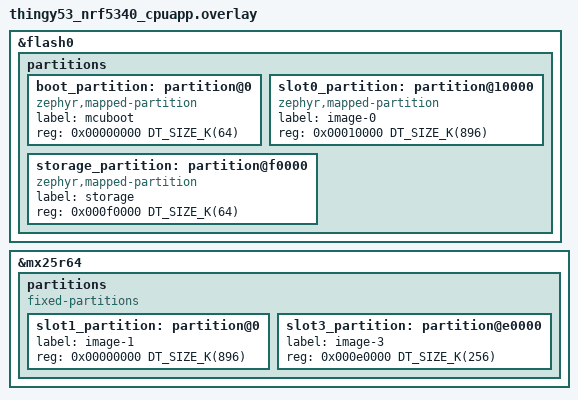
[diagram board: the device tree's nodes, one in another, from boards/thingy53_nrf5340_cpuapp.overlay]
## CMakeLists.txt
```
#
# Copyright (c) 2022 Nordic Semiconductor ASA
#
# SPDX-License-Identifier: LicenseRef-Nordic-5-Clause
#

cmake_minimum_required(VERSION 3.20.0)

find_package(Zephyr REQUIRED HINTS $ENV{ZEPHYR_BASE})
project(wifi_ble_provisioning)

target_sources(app PRIVATE src/main.c)

zephyr_library_include_directories($<TARGET_PROPERTY:wifi_prov_core,BINARY_DIR>)

target_link_libraries(app PRIVATE wifi_prov_ble)
```

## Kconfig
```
#
# Copyright (c) 2022 Nordic Semiconductor ASA
#
# SPDX-License-Identifier: LicenseRef-Nordic-5-Clause
#
menu "Wi-Fi Provisioning Sample"

config WIFI_PROV_ADV_DATA_UPDATE
	bool "Enable periodic update of advertisement data"
	default y

if WIFI_PROV_ADV_DATA_UPDATE

	config WIFI_PROV_ADV_DATA_UPDATE_INTERVAL
		int "Periodic update interval in second"
		default 5

endif # WIFI_PROV_ADV_DATA_UPDATE

endmenu

source "Kconfig.zephyr"
```

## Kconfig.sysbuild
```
#
# Copyright (c) 2023 Nordic Semiconductor
#
# SPDX-License-Identifier: LicenseRef-Nordic-5-Clause
#

source "${ZEPHYR_NRF_MODULE_DIR}/samples/wifi/Kconfig.sysbuild.nrf70"
source "share/sysbuild/Kconfig"

config NRF_DEFAULT_IPC_RADIO
	default y
```

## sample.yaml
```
sample:
  description: Bluetooth Low Energy Wi-Fi provision sample
  name: Bluetooth LE Wi-Fi provision
tests:
  sample.nrf7002.ble-wifi-provision:
    sysbuild: true
    build_only: true
    integration_platforms:
      - nrf7002dk/nrf5340/cpuapp
    platform_allow: nrf7002dk/nrf5340/cpuapp
    tags:
      - ci_build
      - sysbuild
      - ci_samples_wifi
  sample.nrf7001.ble-wifi-provision:
    sysbuild: true
    build_only: true
    integration_platforms:
      - nrf7002dk/nrf5340/cpuapp/nrf7001
    platform_allow: nrf7002dk/nrf5340/cpuapp/nrf7001
    tags:
      - ci_build
      - sysbuild
      - ci_samples_wifi
    skip: true
  sample.nrf7002_eks.ble-wifi-provision:
    sysbuild: true
    build_only: true
    extra_args: SHIELD=nrf7002ek
    integration_platforms:
      - nrf5340dk/nrf5340/cpuapp
    platform_allow: nrf5340dk/nrf5340/cpuapp
    tags:
      - ci_build
      - sysbuild
      - ci_samples_wifi
  sample.nrf7001_eks.ble-wifi-provision:
    sysbuild: true
    build_only: true
    extra_args: SHIELD=nrf7002ek_nrf7001
    integration_platforms:
      - nrf5340dk/nrf5340/cpuapp
    platform_allow: nrf5340dk/nrf5340/cpuapp
    tags:
      - ci_build
      - sysbuild
      - ci_samples_wifi
  sample.nrf7002_eb.thingy53.ble-wifi-provision:
    sysbuild: true
    build_only: true
    extra_args: ble_SHIELD=nrf7002eb
    integration_platforms:
      - thingy53/nrf5340/cpuapp
    platform_allow: thingy53/nrf5340/cpuapp
    tags:
      - ci_build
      - sysbuild
      - ci_samples_wifi
  sample.nrf7002eb2.nrf54l15.ble-wifi-provision:
    sysbuild: true
    build_only: true
    extra_args:
      - ble_SHIELD="nrf7002eb2"
      - ble_SNIPPET=nrf70-wifi
      - CONFIG_NRF_WIFI_CTRL_HEAP_SIZE=25000
    integration_platforms:
      - nrf54l15dk/nrf54l15/cpuapp
    platform_allow:
      - nrf54l15dk/nrf54l15/cpuapp
    tags:
      - ci_build
      - sysbuild
      - ci_samples_wifi
  sample.nrf7002eb_interposer_p1.nrf54h20.ble-wifi-provision:
    sysbuild: true
    build_only: true
    extra_args:
      - ble_SHIELD="nrf7002eb_interposer_p1;nrf7002eb"
      - ble_SNIPPET=nrf70-wifi
    integration_platforms:
      - nrf54h20dk/nrf54h20/cpuapp
    platform_allow:
      - nrf54h20dk/nrf54h20/cpuapp
    tags:
      - ci_build
      - sysbuild
      - ci_samples_wifi
  sample.54lm20dk.nrf7002eb2.ble-wifi-provision:
    sysbuild: true
    build_only: true
    extra_args:
      - ble_SHIELD="nrf7002eb2"
    integration_platforms:
      - nrf54lm20dk/nrf54lm20a/cpuapp
      - nrf54lm20dk/nrf54lm20b/cpuapp
    platform_allow:
      - nrf54lm20dk/nrf54lm20a/cpuapp
      - nrf54lm20dk/nrf54lm20b/cpuapp
    tags:
      - ci_build
      - sysbuild
      - ci_samples_wifi
  sample.nrf7120dk.ble-wifi-provision:
    sysbuild: true
    build_only: true
    extra_args:
      - EXTRA_DTC_OVERLAY_FILE=${ZEPHYR_NRFXLIB_MODULE_DIR}/nrf71_wifi/bins/0.1.0/nrf7120_wifi_patch.dtsi
      - CONFIG_WIFI_NRF71_PATCH=y
    integration_platforms:
      - nrf7120dk/nrf7120/cpuapp
      - nrf7120dk/nrf7120/cpuapp/ns
    platform_allow:
      - nrf7120dk/nrf7120/cpuapp
      - nrf7120dk/nrf7120/cpuapp/ns
    tags:
      - ci_build
      - sysbuild
      - ci_samples_nrf71_wifi
```

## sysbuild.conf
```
#
# Copyright (c) 2024 Nordic Semiconductor ASA
#
# SPDX-License-Identifier: LicenseRef-Nordic-5-Clause
#

SB_CONFIG_WIFI_NRF70=y
SB_CONFIG_PARTITION_MANAGER=n
```

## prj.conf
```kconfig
#
# Copyright (c) 2022 Nordic Semiconductor ASA
#
# SPDX-License-Identifier: LicenseRef-Nordic-5-Clause
#
CONFIG_WIFI=y

# WPA supplicant
CONFIG_WIFI_NM_WPA_SUPPLICANT=y

# Networking
CONFIG_NETWORKING=y
CONFIG_NET_SOCKETS=y
CONFIG_NET_LOG=y
CONFIG_NET_IPV6=n
CONFIG_NET_IPV4=y
CONFIG_NET_UDP=y
CONFIG_NET_TCP=y
CONFIG_NET_DHCPV4=y
CONFIG_DNS_RESOLVER=y

CONFIG_NET_STATISTICS=y

CONFIG_NET_PKT_RX_COUNT=8
CONFIG_NET_PKT_TX_COUNT=8

# Below section is the primary contributor to SRAM and is currently
# tuned for performance, but this will be revisited in the future.
CONFIG_NET_BUF_RX_COUNT=16
CONFIG_NET_BUF_TX_COUNT=16
CONFIG_HEAP_MEM_POOL_SIZE=44240
CONFIG_NET_TC_TX_COUNT=1

CONFIG_NET_IF_UNICAST_IPV4_ADDR_COUNT=1
CONFIG_NET_MAX_CONTEXTS=5
CONFIG_NET_CONTEXT_SYNC_RECV=y

CONFIG_INIT_STACKS=y

CONFIG_NET_L2_ETHERNET=y

CONFIG_NET_CONFIG_SETTINGS=y
CONFIG_NET_CONFIG_INIT_TIMEOUT=0

CONFIG_NET_CONFIG_MY_IPV4_ADDR="192.165.100.150"
CONFIG_NET_CONFIG_PEER_IPV4_ADDR="192.165.100.1"

CONFIG_ZVFS_POLL_MAX=10

# Memories
CONFIG_MAIN_STACK_SIZE=5200
CONFIG_NET_TX_STACK_SIZE=4096
CONFIG_NET_RX_STACK_SIZE=4096

# Debugging
CONFIG_STACK_SENTINEL=y
CONFIG_DEBUG_COREDUMP=y
CONFIG_DEBUG_COREDUMP_BACKEND_LOGGING=y
CONFIG_DEBUG_COREDUMP_MEMORY_DUMP_MIN=y

# Kernel options
CONFIG_ENTROPY_GENERATOR=y

# Logging
CONFIG_LOG=y

CONFIG_NET_L2_WIFI_MGMT=y

CONFIG_BT=y
CONFIG_BT_SMP=y
CONFIG_BT_PERIPHERAL=y

CONFIG_BT_BUF_ACL_RX_SIZE=151
CONFIG_BT_L2CAP_TX_MTU=147
CONFIG_BT_BUF_ACL_TX_SIZE=151

# Increased BT RX stack size because BLE and Wi-Fi operations
# run in the same BT RX workqueue thread during provisioning.
CONFIG_BT_RX_STACK_SIZE=22000
CONFIG_BT_BONDABLE=n
CONFIG_BT_DEVICE_NAME_DYNAMIC=y

CONFIG_FLASH=y
CONFIG_FLASH_PAGE_LAYOUT=y
CONFIG_FLASH_MAP=y

CONFIG_NVS=y

CONFIG_SETTINGS=y
CONFIG_SETTINGS_NVS=y

CONFIG_WIFI_CREDENTIALS=y
CONFIG_WIFI_CREDENTIALS_MAX_ENTRIES=1

CONFIG_NANOPB=y

CONFIG_BT_WIFI_PROV=y
CONFIG_WIFI_PROV_CORE=y
CONFIG_BT_WIFI_PROV_LOG_LEVEL_INF=y

# Setting BT supervision timeout to 75units (750ms) to avoid timeout of BT connection when radio is granted to Wi-Fi during scan.
CONFIG_BT_PERIPHERAL_PREF_TIMEOUT=75

# Similar to shell sample, add this option to ensure the event can get served.
CONFIG_NET_MGMT_EVENT_QUEUE_TIMEOUT=5000
# BT enables MbedTLS heap but uses the default heap size which is not enough for Wi-Fi.
CONFIG_MBEDTLS_HEAP_SIZE=8192
CONFIG_NET_PKT_BUF_TX_DATA_POOL_SIZE=5000
CONFIG_NET_PKT_BUF_RX_DATA_POOL_SIZE=5000
```

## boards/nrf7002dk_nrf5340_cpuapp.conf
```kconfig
#
# Copyright (c) 2026 Nordic Semiconductor ASA
#
# SPDX-License-Identifier: LicenseRef-Nordic-5-Clause
#

#NRF70 specific configuration
CONFIG_WIFI_NRF70=y
CONFIG_NRF70_SR_COEX=y
CONFIG_NRF70_SR_COEX_RF_SWITCH=y
CONFIG_NRF_WIFI_DATA_HEAP_SIZE=118760
```

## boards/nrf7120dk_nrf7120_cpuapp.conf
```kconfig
#
# Copyright (c) 2026 Nordic Semiconductor
#
# SPDX-License-Identifier: LicenseRef-Nordic-5-Clause
#
CONFIG_MPSL_CX=y
```

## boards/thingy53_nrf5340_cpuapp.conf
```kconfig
#
# Copyright (c) 2026 Nordic Semiconductor ASA
#
# SPDX-License-Identifier: LicenseRef-Nordic-5-Clause
#

#NRF70 specific configuration
CONFIG_WIFI_NRF70=y
CONFIG_NRF70_SR_COEX=y
CONFIG_NRF70_SR_COEX_RF_SWITCH=y
```

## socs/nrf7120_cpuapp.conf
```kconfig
CONFIG_WIFI_NRF71_PATCH=y
CONFIG_NRF71_DATA_HEAP_SIZE=118760
```

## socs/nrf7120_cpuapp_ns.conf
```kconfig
CONFIG_NRF71_WIFI_PATCH=y
CONFIG_NRF71_WIFI_DATA_HEAP_SIZE=118760
```

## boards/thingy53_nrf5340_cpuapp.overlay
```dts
/*
 * Copyright (c) 2024 Nordic Semiconductor ASA
 *
 * SPDX-License-Identifier: LicenseRef-Nordic-5-Clause
 */

/* Override flash partitions to provide slot0_partition large enough for
 * the ble provisioning app (~700 KB).
 */

/delete-node/ &boot_partition;
/delete-node/ &slot0_partition;
/delete-node/ &slot1_partition;
/delete-node/ &storage_partition;

&flash0 {
	partitions {
		ranges;
		#address-cells = <1>;
		#size-cells = <1>;

		boot_partition: partition@0 {
			compatible = "zephyr,mapped-partition";
			label = "mcuboot";
			reg = <0x00000000 DT_SIZE_K(64)>;
		};

		slot0_partition: partition@10000 {
			compatible = "zephyr,mapped-partition";
			label = "image-0";
			reg = <0x00010000 DT_SIZE_K(896)>;
		};

		storage_partition: partition@f0000 {
			compatible = "zephyr,mapped-partition";
			label = "storage";
			reg = <0x000f0000 DT_SIZE_K(64)>;
		};
	};
};

&mx25r64 {
	status = "okay";

	partitions {
		compatible = "fixed-partitions";
		#address-cells = <1>;
		#size-cells = <1>;

		slot1_partition: partition@0 {
			label = "image-1";
			reg = <0x00000000 DT_SIZE_K(896)>;
		};

		slot3_partition: partition@e0000 {
			label = "image-3";
			reg = <0x000e0000 DT_SIZE_K(256)>;
		};
	};
};
```

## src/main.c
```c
/*
 * Copyright (c) 2022 Nordic Semiconductor ASA
 *
 * SPDX-License-Identifier: LicenseRef-Nordic-5-Clause
 */
#include <zephyr/types.h>
#include <stddef.h>
#include <string.h>
#include <errno.h>
#include <zephyr/sys/printk.h>
#include <zephyr/kernel.h>
#include <zephyr/bluetooth/bluetooth.h>
#include <zephyr/bluetooth/hci.h>
#include <zephyr/bluetooth/conn.h>
#include <zephyr/bluetooth/uuid.h>
#include <zephyr/bluetooth/gatt.h>

#include <zephyr/net/wifi.h>
#include <zephyr/net/wifi_mgmt.h>
#include <zephyr/net/wifi_credentials.h>

#include <net/wifi_prov_core/wifi_prov_core.h>
#include <bluetooth/services/wifi_provisioning.h>

#ifdef CONFIG_WIFI_PROV_ADV_DATA_UPDATE
#define ADV_DATA_UPDATE_INTERVAL      CONFIG_WIFI_PROV_ADV_DATA_UPDATE_INTERVAL
#endif /* CONFIG_WIFI_PROV_ADV_DATA_UPDATE */

#define ADV_PARAM_UPDATE_DELAY        1

#define ADV_DATA_VERSION_IDX          (BT_UUID_SIZE_128 + 0)
#define ADV_DATA_FLAG_IDX             (BT_UUID_SIZE_128 + 1)
#define ADV_DATA_FLAG_PROV_STATUS_BIT BIT(0)
#define ADV_DATA_FLAG_CONN_STATUS_BIT BIT(1)
#define ADV_DATA_RSSI_IDX             (BT_UUID_SIZE_128 + 3)

#define PROV_BT_LE_ADV_PARAM_FAST BT_LE_ADV_PARAM(BT_LE_ADV_OPT_CONN, \
						BT_GAP_ADV_FAST_INT_MIN_2, \
						BT_GAP_ADV_FAST_INT_MAX_2, NULL)

#define PROV_BT_LE_ADV_PARAM_SLOW BT_LE_ADV_PARAM(BT_LE_ADV_OPT_CONN, \
						BT_GAP_ADV_SLOW_INT_MIN, \
						BT_GAP_ADV_SLOW_INT_MAX, NULL)

#define ADV_DAEMON_STACK_SIZE 4096
#define ADV_DAEMON_PRIORITY 5

K_THREAD_STACK_DEFINE(adv_daemon_stack_area, ADV_DAEMON_STACK_SIZE);

static struct k_work_q adv_daemon_work_q;

static uint8_t device_name[] = {'P', 'V', '0', '0', '0', '0', '0', '0'};

static uint8_t prov_svc_data[] = {BT_UUID_PROV_VAL, 0x00, 0x00, 0x00, 0x00};

static const struct bt_data ad[] = {
	BT_DATA_BYTES(BT_DATA_FLAGS, (BT_LE_AD_GENERAL | BT_LE_AD_NO_BREDR)),
	BT_DATA_BYTES(BT_DATA_UUID128_ALL, BT_UUID_PROV_VAL),
	BT_DATA(BT_DATA_NAME_COMPLETE, device_name, sizeof(device_name)),
};

static const struct bt_data sd[] = {
	BT_DATA(BT_DATA_SVC_DATA128, prov_svc_data, sizeof(prov_svc_data)),
};

static struct k_work_delayable update_adv_param_work;
static struct k_work_delayable update_adv_data_work;

static void update_wifi_status_in_adv(void)
{
	int rc;
	struct net_if *iface = net_if_get_default();
	struct wifi_iface_status status = { 0 };

	prov_svc_data[ADV_DATA_VERSION_IDX] = PROV_SVC_VER;

	/* If no config, mark it as unprovisioned. */
	if (!wifi_prov_state_get()) {
		prov_svc_data[ADV_DATA_FLAG_IDX] &= ~ADV_DATA_FLAG_PROV_STATUS_BIT;
	} else {
		prov_svc_data[ADV_DATA_FLAG_IDX] |= ADV_DATA_FLAG_PROV_STATUS_BIT;
	}

	rc = net_mgmt(NET_REQUEST_WIFI_IFACE_STATUS, iface, &status,
				sizeof(struct wifi_iface_status));
	/* If WiFi is not connected or error occurs, mark it as not connected. */
	if ((rc != 0) || (status.state < WIFI_STATE_ASSOCIATED)) {
		prov_svc_data[ADV_DATA_FLAG_IDX] &= ~ADV_DATA_FLAG_CONN_STATUS_BIT;
		prov_svc_data[ADV_DATA_RSSI_IDX] = INT8_MIN;
	} else {
		/* WiFi is connected. */
		prov_svc_data[ADV_DATA_FLAG_IDX] |= ADV_DATA_FLAG_CONN_STATUS_BIT;
		/* Currently cannot retrieve RSSI. Use a dummy number. */
		prov_svc_data[ADV_DATA_RSSI_IDX] = status.rssi;
	}
}

static void connected(struct bt_conn *conn, uint8_t err)
{
	char addr[BT_ADDR_LE_STR_LEN];

	if (err) {
		printk("BT Connection failed (err 0x%02x).\n", err);
		return;
	}

	bt_addr_le_to_str(bt_conn_get_dst(conn), addr, sizeof(addr));
	printk("BT Connected: %s", addr);

	k_work_cancel_delayable(&update_adv_data_work);
}

static void disconnected(struct bt_conn *conn, uint8_t reason)
{
	char addr[BT_ADDR_LE_STR_LEN];

	bt_addr_le_to_str(bt_conn_get_dst(conn), addr, sizeof(addr));
	printk("BT Disconnected: %s (reason 0x%02x).\n", addr, reason);

	k_work_reschedule_for_queue(&adv_daemon_work_q, &update_adv_param_work,
				K_SECONDS(ADV_PARAM_UPDATE_DELAY));
	k_work_reschedule_for_queue(&adv_daemon_work_q, &update_adv_data_work, K_NO_WAIT);
}

static void identity_resolved(struct bt_conn *conn, const bt_addr_le_t *rpa,
				const bt_addr_le_t *identity)
{
	char addr_identity[BT_ADDR_LE_STR_LEN];
	char addr_rpa[BT_ADDR_LE_STR_LEN];

	bt_addr_le_to_str(identity, addr_identity, sizeof(addr_identity));
	bt_addr_le_to_str(rpa, addr_rpa, sizeof(addr_rpa));

	printk("BT Identity resolved %s -> %s.\n", addr_rpa, addr_identity);
}

static void security_changed(struct bt_conn *conn, bt_security_t level,
				enum bt_security_err err)
{
	char addr[BT_ADDR_LE_STR_LEN];

	bt_addr_le_to_str(bt_conn_get_dst(conn), addr, sizeof(addr));

	if (!err) {
		printk("BT Security changed: %s level %u.\n", addr, level);
	} else {
		printk("BT Security failed: %s level %u err %d.\n", addr, level,
			   err);
	}
}

BT_CONN_CB_DEFINE(conn_callbacks) = {
	.connected = connected,
	.disconnected = disconnected,
	.identity_resolved = identity_resolved,
	.security_changed = security_changed,
};

static void auth_cancel(struct bt_conn *conn)
{
	char addr[BT_ADDR_LE_STR_LEN];

	bt_addr_le_to_str(bt_conn_get_dst(conn), addr, sizeof(addr));

	printk("BT Pairing cancelled: %s.\n", addr);
}

static struct bt_conn_auth_cb auth_cb_display = {
	.cancel = auth_cancel,
};

static void pairing_complete(struct bt_conn *conn, bool bonded)
{
	char addr[BT_ADDR_LE_STR_LEN];

	bt_addr_le_to_str(bt_conn_get_dst(conn), addr, sizeof(addr));
	printk("BT pairing completed: %s, bonded: %d\n", addr, bonded);
}

static void pairing_failed(struct bt_conn *conn, enum bt_security_err reason)
{
	printk("BT Pairing Failed (%d). Disconnecting.\n", reason);
	bt_conn_disconnect(conn, BT_HCI_ERR_AUTH_FAIL);
}

static struct bt_conn_auth_info_cb auth_info_cb_display = {

	.pairing_complete = pairing_complete,
	.pairing_failed = pairing_failed,
};

static void update_adv_data_task(struct k_work *item)
{
	int rc;

	update_wifi_status_in_adv();
	rc = bt_le_adv_update_data(ad, ARRAY_SIZE(ad), sd, ARRAY_SIZE(sd));
	if (rc != 0) {
		printk("Cannot update advertisement data, err = %d\n", rc);
	}
#ifdef CONFIG_WIFI_PROV_ADV_DATA_UPDATE
	k_work_reschedule_for_queue(&adv_daemon_work_q, &update_adv_data_work,
				K_SECONDS(ADV_DATA_UPDATE_INTERVAL));
#endif /* CONFIG_WIFI_PROV_ADV_DATA_UPDATE */
}

static void update_adv_param_task(struct k_work *item)
{
	int rc;

	rc = bt_le_adv_stop();
	if (rc != 0) {
		printk("Cannot stop advertisement: err = %d\n", rc);
		return;
	}

	rc = bt_le_adv_start(prov_svc_data[ADV_DATA_FLAG_IDX] & ADV_DATA_FLAG_PROV_STATUS_BIT ?
		PROV_BT_LE_ADV_PARAM_SLOW : PROV_BT_LE_ADV_PARAM_FAST,
		ad, ARRAY_SIZE(ad), sd, ARRAY_SIZE(sd));
	if (rc != 0) {
		printk("Cannot start advertisement: err = %d\n", rc);
	}
}

static void byte_to_hex(char *ptr, uint8_t byte, char base)
{
	int i, val;

	for (i = 0, val = (byte & 0xf0) >> 4; i < 2; i++, val = byte & 0x0f) {
		if (val < 10) {
			*ptr++ = (char) (val + '0');
		} else {
			*ptr++ = (char) (val - 10 + base);
		}
	}
}

static void update_dev_name(struct net_linkaddr *mac_addr)
{
	byte_to_hex(&device_name[2], mac_addr->addr[3], 'A');
	byte_to_hex(&device_name[4], mac_addr->addr[4], 'A');
	byte_to_hex(&device_name[6], mac_addr->addr[5], 'A');
}

int main(void)
{
	int rc;
	struct net_if *iface = net_if_get_default();
	struct net_linkaddr *mac_addr = net_if_get_link_addr(iface);
	char device_name_str[sizeof(device_name) + 1];
	/* Sleep 1 seconds to allow initialization of wifi driver. */
	k_sleep(K_SECONDS(1));

	bt_conn_auth_cb_register(&auth_cb_display);
	bt_conn_auth_info_cb_register(&auth_info_cb_display);

	rc = bt_enable(NULL);
	if (rc) {
		printk("Bluetooth init failed (err %d).\n", rc);
		return 0;
	}

	printk("Bluetooth initialized.\n");

	rc = wifi_prov_init();
	if (rc == 0) {
		printk("Wi-Fi provisioning service starts successfully.\n");
	} else {
		printk("Error occurs when initializing Wi-Fi provisioning service.\n");
		return 0;
	}

	/* Prepare advertisement data */
	if (mac_addr) {
		update_dev_name(mac_addr);
	}
	device_name_str[sizeof(device_name_str) - 1] = '\0';
	memcpy(device_name_str, device_name, sizeof(device_name));
	bt_set_name(device_name_str);

	rc = bt_le_adv_start(prov_svc_data[ADV_DATA_FLAG_IDX] & ADV_DATA_FLAG_PROV_STATUS_BIT ?
		PROV_BT_LE_ADV_PARAM_SLOW : PROV_BT_LE_ADV_PARAM_FAST,
		ad, ARRAY_SIZE(ad), sd, ARRAY_SIZE(sd));
	if (rc) {
		printk("BT Advertising failed to start (err %d)\n", rc);
		return 0;
	}
	printk("BT Advertising successfully started.\n");

	update_wifi_status_in_adv();

	k_work_queue_init(&adv_daemon_work_q);
	k_work_queue_start(&adv_daemon_work_q, adv_daemon_stack_area,
			K_THREAD_STACK_SIZEOF(adv_daemon_stack_area), ADV_DAEMON_PRIORITY,
			NULL);

	k_work_init_delayable(&update_adv_param_work, update_adv_param_task);
	k_work_init_delayable(&update_adv_data_work, update_adv_data_task);
#ifdef CONFIG_WIFI_PROV_ADV_DATA_UPDATE
	k_work_schedule_for_queue(&adv_daemon_work_q, &update_adv_data_work,
				K_SECONDS(ADV_DATA_UPDATE_INTERVAL));
#endif /* CONFIG_WIFI_PROV_ADV_DATA_UPDATE */

	/* Apply stored wifi credential */
	net_mgmt(NET_REQUEST_WIFI_CONNECT_STORED, iface, NULL, 0);

	return 0;
}
```
